# psoc4axx register map
Vendor: Cypress Semiconductor; Series: PSoC4Axx; File version: 1.0
CPU: CM0PLUS r0p1, little endian, no MPU, no FPU, VTOR, 2 interrupt priority bits
Registers are 32-bit, read-write, reset 0x0 unless marked. A register's access mark holds for its fields unless they carry their own. Offsets are from the block's base; [hi:lo] are bit positions; {n}, {i} and the like mark numbered series; 'fields as' and 'values as' point back to an identical list; <NAME> marks a mode.

## LCD — LCD Controller Block
Base 0x400B0000
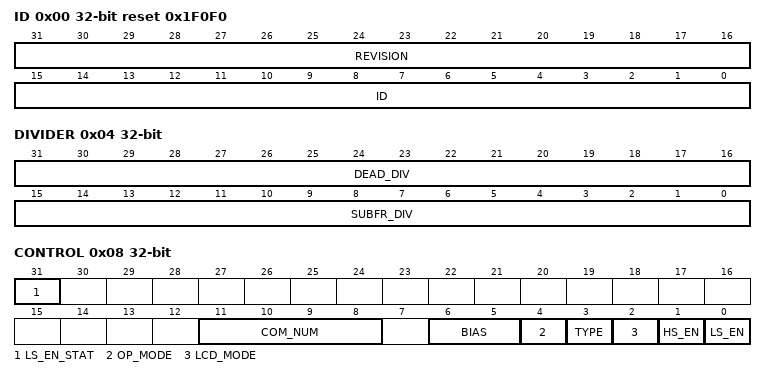
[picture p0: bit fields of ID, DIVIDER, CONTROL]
0x00 ID ro reset 0x1F0F0 — ID & Revision
  [31:16] REVISION — the version number is 0x0001
  [15:0] ID — the ID of LCD controller peripheral is 0xF0F0
0x04 DIVIDER — LCD Divider Register
  [31:16] DEAD_DIV — Length of the dead time period in cycles. When set to zero, no dead time period exists.
  [15:0] SUBFR_DIV — Input clock frequency divide value, to generate the 1/4 sub-frame period. The sub-frame period is 4*(SUBFR_DIV+1) cycles long.
0x08 CONTROL — LCD Configuration Register
  [31] LS_EN_STAT ro — LS enable status bit. This bit is a copy of LS_EN that is synchronized to the low speed clock domain and back to the system clock domain. Firmware can use this bit to observe whether LS_EN has taken effect in the low speed clock domain. Firmware should never change the configuration for the LS generator without ensuring this bit is 0. The following procedure should be followed to disable the LS generator: 1. If LS_EN=0 we are done. Exit the procedure. 2. Check that LS_EN_STAT=1. If not, wait until it is. This will catch the case of a recent enable (LS_EN=1) that has not taken effect yet. 3. Set LS_EN=0. 4. Wait until LS_EN_STAT=0.
  [11:8] COM_NUM — The number of COM connections minus 2. So: 0: 2 COM's 1: 3 COM's ... 13: 15 COM's 14: 16 COM's 15: undefined
  [6:5] BIAS — PWM bias selection
    0=HALF (1/2 Bias); 1=THIRD (1/3 Bias); 2=FOURTH (1/4 Bias (not supported by LS generator)); 3=FIFTH (1/5 Bias (not supported by LS generator))
  [4] OP_MODE — Driving mode configuration
    0=PWM (PWM Mode); 1=CORRELATION (Digital Correlation Mode)
  [3] TYPE — LCD driving waveform type configuration.
    0=TYPE_A (Type A - Each frame addresses each COM pin only once with a balanced (DC=0) waveform.); 1=TYPE_B (Type B - Each frame addresses each COM pin twice in sequence with a positive and negative waveform that together are balanced (DC=0).)
  [2] LCD_MODE — HS/LS Mode selection
    0=LS (Select Low Speed (32kHz) Generator (Works in Active, Sleep and DeepSleep power modes).); 1=HS (Select High Speed (system clock) Generator (Works in Active and Sleep power modes only).)
  [1] HS_EN — High speed (HS) generator enable 1: enable 0: disable
  [0] LS_EN — Low speed (LS) generator enable 1: enable 0: disable
{0x100+4i} DATA0[{i}] (i=0..7) — LCD Pin Data Registers
  [31:0] DATA — Bits [4i+3:4i] represent the pin data for pin [i] for COMS 1-4 (COM1 is lsb).
{0x200+4i} DATA1[{i}] (i=0..7) — LCD Pin Data Registers
  [31:0] DATA — Bits [4i+3:4i] represent the pin data for pin [i] for COMS 5-8 (COM5 is lsb).
{0x300+4i} DATA2[{i}] (i=0..7) — LCD Pin Data Registers
  [31:0] DATA — Bits [4i+3:4i] represent the pin data for pin [i] for COMS 9-12 (COM9 is lsb).
{0x400+4i} DATA3[{i}] (i=0..7) — LCD Pin Data Registers
  [31:0] DATA — Bits [4i+3:4i] represent the pin data for pin [i] for COMS 13-16 (COM13 is lsb).

## LPCOMP — Low Power Comparators
Base 0x400E0000
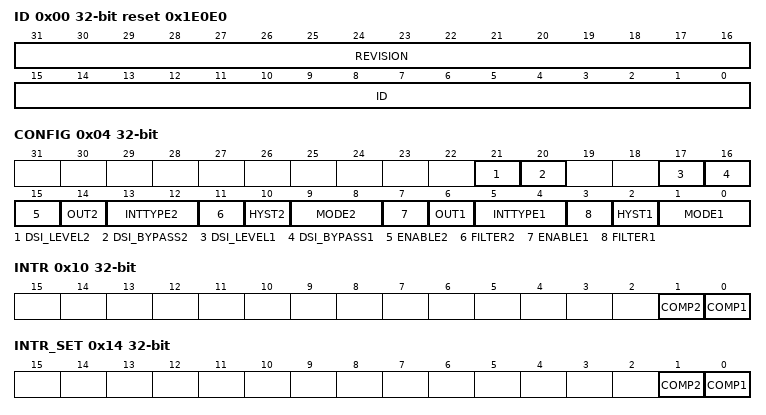
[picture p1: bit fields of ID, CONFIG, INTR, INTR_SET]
0x00 ID ro reset 0x1E0E0 — ID & Revision
  [31:16] REVISION — the version number is 0x0001
  [15:0] ID — the ID of LPCOMP peripheral is 0xE0E0
0x04 CONFIG — LPCOMP Configuration Register
  [21] DSI_LEVEL2 — Opamp2 comparator DSI (trigger) out level : 0=pulse, 1=level
  [20] DSI_BYPASS2 — Opamp2 bypass comparator output synchronization for DSI output: 0=synchronize (level or pulse), 1=bypass (output async) Note that in DeepSleep mode this bit needs to be set to observe the DSI output on the dedicated pin.
  [17] DSI_LEVEL1 — Opamp1 comparator DSI (trigger) out level : 0=pulse, 1=level
  [16] DSI_BYPASS1 — Opamp1 bypass comparator output synchronization for DSI output: 0=synchronize (level or pulse), 1=bypass (output async) Note that in DeepSleep mode this bit needs to be set to observe the DSI output on the dedicated pin.
  [15] ENABLE2 — Enable comparator #2
  [14] OUT2 ro — Current output value of the comparator.
  [13:12] INTTYPE2 — Sets which edge will trigger an IRQ
    0=DISABLE (Disabled, no interrupts will be detected); 1=RISING (Rising edge); 2=FALLING (Falling edge); 3=BOTH (Both rising and falling edges)
  [11] FILTER2
  [10] HYST2 — Add 10mV hysteresis to the comparator - 0: Enable Hysteresis - 1: Disable Hysteresis
  [9:8] MODE2 — Operating mode for the comparator
    0=SLOW (Slow operating mode (uses less power, <50uA)); 1=FAST (Fast operating mode (uses more power, <400uA)); 2=ULP (Ultra low power operting mode (uses ~2-4uA))
  [7] ENABLE1 — Enable comparator #1
  [6] OUT1 ro — Current output value of the comparator.
  [5:4] INTTYPE1 — Sets which edge will trigger an IRQ
    values as INTTYPE2
  [3] FILTER1
  [2] HYST1 — Add 10mV hysteresis to the comparator - 0: Enable Hysteresis - 1: Disable Hysteresis
  [1:0] MODE1 — Operating mode for the comparator
    values as MODE2
0x10 INTR — LPCOMP Interrupt request register
  [1] COMP2 — Comparator 2 Interrupt: hardware sets this interrupt when comparator 0 triggers. Write with '1' to clear bit.
  [0] COMP1 — Comparator 1 Interrupt: hardware sets this interrupt when comparator 0 triggers. Write with '1' to clear bit.
0x14 INTR_SET — LPCOMP Interrupt set register
  [1] COMP2 — Write with '1' to set corresponding bit in interrupt request register.
  [0] COMP1 — Write with '1' to set corresponding bit in interrupt request register.
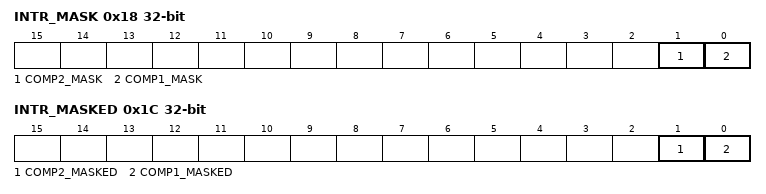
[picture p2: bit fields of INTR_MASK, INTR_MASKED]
0x18 INTR_MASK — LPCOMP Interrupt request mask
  [1] COMP2_MASK — Mask bit for corresponding bit in interrupt request register.
  [0] COMP1_MASK — Mask bit for corresponding bit in interrupt request register.
0x1C INTR_MASKED ro — LPCOMP Interrupt request masked
  [1] COMP2_MASKED — Logical and of corresponding request and mask bits.
  [0] COMP1_MASKED — Logical and of corresponding request and mask bits.
0xFF00 TRIM1 — LPCOMP Trim Register
  [4:0] COMP1_TRIMA — Trim A for Comparator #1
0xFF04 TRIM2 — LPCOMP Trim Register
  [4:0] COMP1_TRIMB — Trim B for Comparator #1
0xFF08 TRIM3 — LPCOMP Trim Register
  [4:0] COMP2_TRIMA — Trim A for Comparator #2
0xFF0C TRIM4 — LPCOMP Trim Register
  [4:0] COMP2_TRIMB — Trim B for Comparator #2

## SPCIF — Flash Control Interface
Base 0x40110000
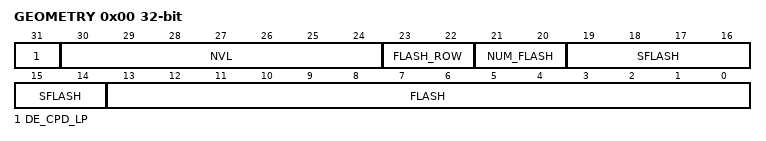
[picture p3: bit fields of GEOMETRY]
0x00 GEOMETRY (reset mask 0x80000000) — Flash/NVL geometry information
  [31] DE_CPD_LP — 0': SRAM busy wait loop has not been copied. '1': Busy wait loop has been written into SRAM.
  [30:24] NVL ro — NVLatch size in Byte multiples (chip dependent): '0': 0 Bytes '1': 1 Byte ... '127': 127 Bytes
  [23:22] FLASH_ROW ro — Page size in 64 Byte multiples (chip dependent): '0': 64 byte '1': 128 byte '2': 192 byte '3': 256 byte The page size is used to detemine the number of Bytes in a page for Flash page based operations (e.g. PGM_PAGE). Note: the field name FLASH_ROW is misleading, as this field specifies the number of Bytes in a page, rather than the number of Bytes in a row. In a single plane flash macro architecture, a page consists of a single row. However, in a multi plane flash macro architecture, a page consists of multiple rows from different planes.
  [21:20] NUM_FLASH ro — Number of flash macros (chip dependent): '0': 1 flash macro '1': 2 flash macros '2': 3 flash macros '3': 4 flash macros
  [19:14] SFLASH ro — Supervisory flash capacity in 256 Byte multiples (chip dependent). If multiple flash macros are present, this field provides the supervisory flash capacity of all flash macros together: '0': 256 Bytes. '1': 2*256 Bytes. ... '63': 64*256 Bytes.
  [13:0] FLASH ro — Regular flash capacity in 256 Byte multiples (chip dependent). If multiple flash macros are present, this field provides the flash capacity of all flash macros together: '0': 256 Bytes. '1': 2*256 Bytes. ... '16383': 16384*256 Bytes.
0x1C NVL_WR_DATA — NVL write data register
  [7:0] DATA — Data to be written to NVLatch array
0x7F0 INTR — SPCIF interrupt request register
  [0] TIMER — Timer counter value reaches '0'. Set to '1', when event is detected. Write INTR field with '1', to clear bit. Write INTR_SET field with '1', to set bit.
0x7F4 INTR_SET — SPCIF interrupt set request register
  [0] TIMER — Write INTR_SET field with '1' to set corresponding INTR field.
0x7F8 INTR_MASK — SPCIF interrupt mask register
  [0] TIMER — Mask for corresponding field in INTR register.
0x7FC INTR_MASKED ro — SPCIF interrupt masked request register
  [0] TIMER — Logical and of corresponding request and mask fields.
